# iorx610 register map
Registers are 8-bit, access not given, no defined reset value unless marked. A register's access mark holds for its fields unless they carry their own. Addresses are absolute; registers are grouped by the start of their names; [hi:lo] are bit positions; {n}, {i} and the like mark numbered series; 'fields as' and 'values as' point back to an identical list.

## SFR (part 2 of 2)
0x871FE ICU
  [1:0] ISELR[254].ISEL
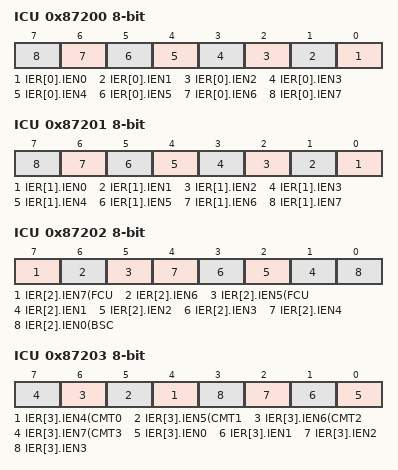
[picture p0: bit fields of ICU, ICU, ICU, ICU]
0x87200 ICU
  [n] IER[0].IEN{n} (n=0..7)
0x87201 ICU
  [n] IER[1].IEN{n} (n=0..7)
0x87202 ICU
  [7] IER[2].IEN7(FCU,FRDYI), [6] IER[2].IEN6, [5] IER[2].IEN5(FCU,FIFERR), [n] IER[2].IEN{n} (n=1..4), [0] IER[2].IEN0(BSC,BUSERR)
0x87203 ICU
  [n] IER[3].IEN{n}(CMT{n-4},CMI{n-4}) (n=4..7), [n] IER[3].IEN{n} (n=0..3)
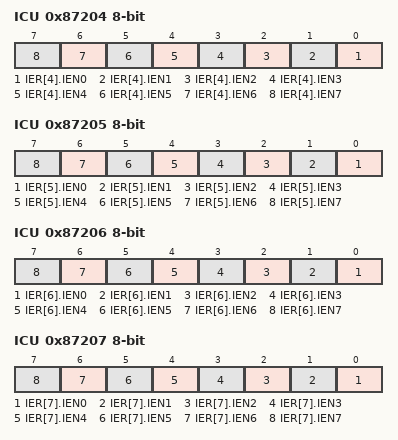
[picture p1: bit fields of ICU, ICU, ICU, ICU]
0x87204 ICU
  [n] IER[4].IEN{n} (n=0..7)
0x87205 ICU
  [n] IER[5].IEN{n} (n=0..7)
0x87206 ICU
  [n] IER[6].IEN{n} (n=0..7)
0x87207 ICU
  [n] IER[7].IEN{n} (n=0..7)
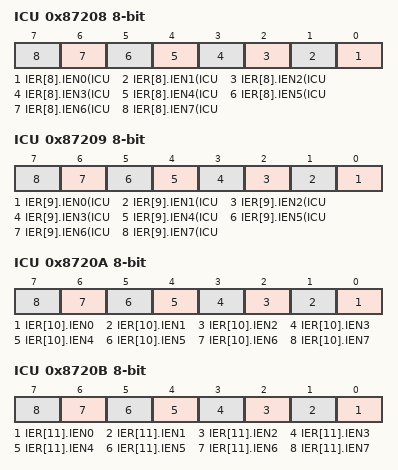
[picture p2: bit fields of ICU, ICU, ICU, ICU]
0x87208 ICU
  [n] IER[8].IEN{n}(ICU,IRQ{n}) (n=0..7)
0x87209 ICU
  [n] IER[9].IEN{n}(ICU,IRQ{n+8}) (n=0..7)
0x8720A ICU
  [n] IER[10].IEN{n} (n=0..7)
0x8720B ICU
  [n] IER[11].IEN{n} (n=0..7)
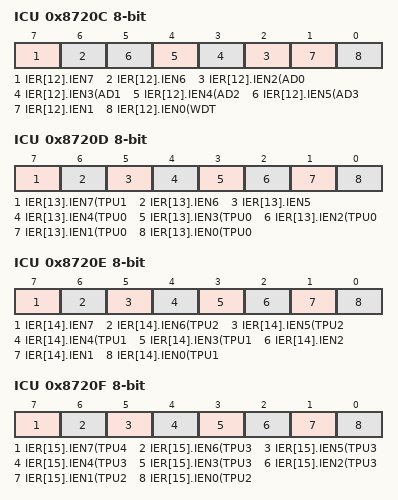
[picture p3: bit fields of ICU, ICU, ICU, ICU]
0x8720C ICU
  [7] IER[12].IEN7, [6] IER[12].IEN6, [n] IER[12].IEN{n}(AD{n-2},ADI{n-2}) (n=2..5), [1] IER[12].IEN1, [0] IER[12].IEN0(WDT,WOVI)
0x8720D ICU
  [7] IER[13].IEN7(TPU1,TGI1A), [6] IER[13].IEN6, [5] IER[13].IEN5, [4] IER[13].IEN4(TPU0,TCI0V), [3] IER[13].IEN3(TPU0,TGI0D), [2] IER[13].IEN2(TPU0,TGI0C), [1] IER[13].IEN1(TPU0,TGI0B), [0] IER[13].IEN0(TPU0,TGI0A)
0x8720E ICU
  [7] IER[14].IEN7, [6] IER[14].IEN6(TPU2,TGI2B), [5] IER[14].IEN5(TPU2,TGI2A), [4] IER[14].IEN4(TPU1,TCI1U), [3] IER[14].IEN3(TPU1,TCI1V), [2] IER[14].IEN2, [1] IER[14].IEN1, [0] IER[14].IEN0(TPU1,TGI1B)
0x8720F ICU
  [7] IER[15].IEN7(TPU4,TGI4A), [6] IER[15].IEN6(TPU3,TCI3V), [5] IER[15].IEN5(TPU3,TGI3D), [4] IER[15].IEN4(TPU3,TGI3C), [3] IER[15].IEN3(TPU3,TGI3B), [2] IER[15].IEN2(TPU3,TGI3A), [1] IER[15].IEN1(TPU2,TCI2U), [0] IER[15].IEN0(TPU2,TCI2V)
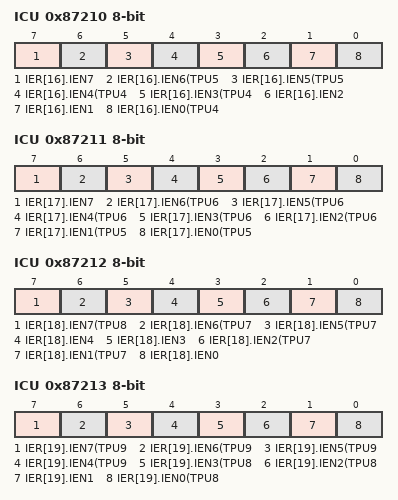
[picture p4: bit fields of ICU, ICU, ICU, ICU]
0x87210 ICU
  [7] IER[16].IEN7, [6] IER[16].IEN6(TPU5,TGI5B), [5] IER[16].IEN5(TPU5,TGI5A), [4] IER[16].IEN4(TPU4,TCI4U), [3] IER[16].IEN3(TPU4,TCI4V), [2] IER[16].IEN2, [1] IER[16].IEN1, [0] IER[16].IEN0(TPU4,TGI4B)
0x87211 ICU
  [7] IER[17].IEN7, [6] IER[17].IEN6(TPU6,TCI6V), [5] IER[17].IEN5(TPU6,TGI6D), [4] IER[17].IEN4(TPU6,TGI6C), [3] IER[17].IEN3(TPU6,TGI6B), [2] IER[17].IEN2(TPU6,TGI6A), [1] IER[17].IEN1(TPU5,TCI5U), [0] IER[17].IEN0(TPU5,TCI5V)
0x87212 ICU
  [7] IER[18].IEN7(TPU8,TGI8A), [6] IER[18].IEN6(TPU7,TCI7U), [5] IER[18].IEN5(TPU7,TCI7V), [4] IER[18].IEN4, [3] IER[18].IEN3, [2] IER[18].IEN2(TPU7,TGI7B), [1] IER[18].IEN1(TPU7,TGI7A), [0] IER[18].IEN0
0x87213 ICU
  [7] IER[19].IEN7(TPU9,TGI9D), [6] IER[19].IEN6(TPU9,TGI9C), [5] IER[19].IEN5(TPU9,TGI9B), [4] IER[19].IEN4(TPU9,TGI9A), [3] IER[19].IEN3(TPU8,TCI8U), [2] IER[19].IEN2(TPU8,TCI8V), [1] IER[19].IEN1, [0] IER[19].IEN0(TPU8,TGI8B)
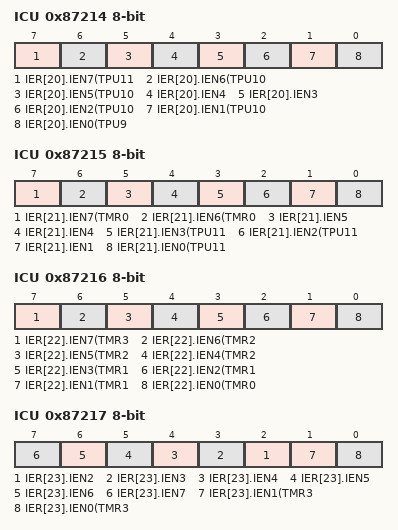
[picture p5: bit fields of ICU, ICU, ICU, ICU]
0x87214 ICU
  [7] IER[20].IEN7(TPU11,TGI11A), [6] IER[20].IEN6(TPU10,TCI10U), [5] IER[20].IEN5(TPU10,TCI10V), [4] IER[20].IEN4, [3] IER[20].IEN3, [2] IER[20].IEN2(TPU10,TGI10B), [1] IER[20].IEN1(TPU10,TGI10A), [0] IER[20].IEN0(TPU9,TCI9V)
0x87215 ICU
  [7] IER[21].IEN7(TMR0,CMIB0), [6] IER[21].IEN6(TMR0,CMIA0), [5] IER[21].IEN5, [4] IER[21].IEN4, [3] IER[21].IEN3(TPU11,TCI11U), [2] IER[21].IEN2(TPU11,TCI11V), [1] IER[21].IEN1, [0] IER[21].IEN0(TPU11,TGI11B)
0x87216 ICU
  [7] IER[22].IEN7(TMR3,CMIA3), [6] IER[22].IEN6(TMR2,OVI2), [5] IER[22].IEN5(TMR2,CMIB2), [4] IER[22].IEN4(TMR2,CMIA2), [3] IER[22].IEN3(TMR1,OVI1), [2] IER[22].IEN2(TMR1,CMIB1), [1] IER[22].IEN1(TMR1,CMIA1), [0] IER[22].IEN0(TMR0,OVI0)
0x87217 ICU
  [n] IER[23].IEN{n} (n=2..7), [1] IER[23].IEN1(TMR3,OVI3), [0] IER[23].IEN0(TMR3,CMIB3)
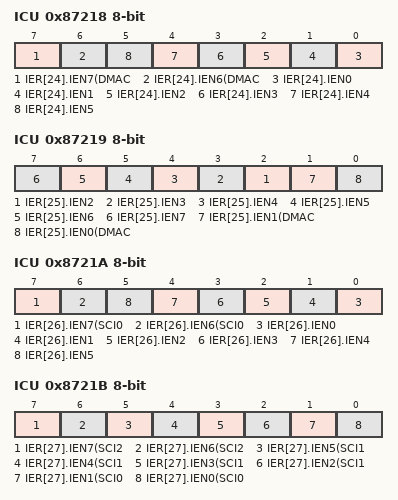
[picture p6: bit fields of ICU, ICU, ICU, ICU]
0x87218 ICU
  [7] IER[24].IEN7(DMAC,DMTEND1), [6] IER[24].IEN6(DMAC,DMTEND0), [n] IER[24].IEN{n} (n=0..5)
0x87219 ICU
  [n] IER[25].IEN{n} (n=2..7), [1] IER[25].IEN1(DMAC,DMTEND3), [0] IER[25].IEN0(DMAC,DMTEND2)
0x8721A ICU
  [7] IER[26].IEN7(SCI0,RXI0), [6] IER[26].IEN6(SCI0,ERI0), [n] IER[26].IEN{n} (n=0..5)
0x8721B ICU
  [7] IER[27].IEN7(SCI2,RXI2), [6] IER[27].IEN6(SCI2,ERI2), [5] IER[27].IEN5(SCI1,TEI1), [4] IER[27].IEN4(SCI1,TXI1), [3] IER[27].IEN3(SCI1,RXI1), [2] IER[27].IEN2(SCI1,ERI1), [1] IER[27].IEN1(SCI0,TEI0), [0] IER[27].IEN0(SCI0,TXI0)
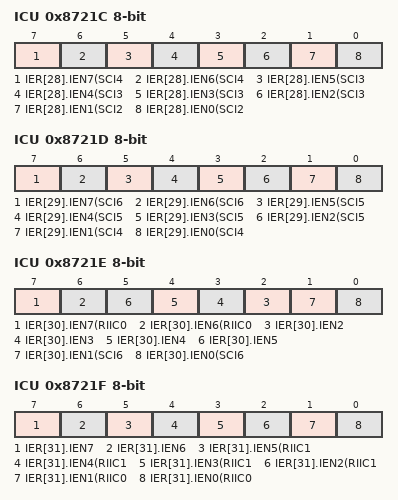
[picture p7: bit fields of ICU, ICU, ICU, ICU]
0x8721C ICU
  [7] IER[28].IEN7(SCI4,RXI4), [6] IER[28].IEN6(SCI4,ERI4), [5] IER[28].IEN5(SCI3,TEI3), [4] IER[28].IEN4(SCI3,TXI3), [3] IER[28].IEN3(SCI3,RXI3), [2] IER[28].IEN2(SCI3,ERI3), [1] IER[28].IEN1(SCI2,TEI2), [0] IER[28].IEN0(SCI2,TXI2)
0x8721D ICU
  [7] IER[29].IEN7(SCI6,RXI6), [6] IER[29].IEN6(SCI6,ERI6), [5] IER[29].IEN5(SCI5,TEI5), [4] IER[29].IEN4(SCI5,TXI5), [3] IER[29].IEN3(SCI5,RXI5), [2] IER[29].IEN2(SCI5,ERI5), [1] IER[29].IEN1(SCI4,TEI4), [0] IER[29].IEN0(SCI4,TXI4)
0x8721E ICU
  [7] IER[30].IEN7(RIIC0,ICRXI0), [6] IER[30].IEN6(RIIC0,ICEEI0), [n] IER[30].IEN{n} (n=2..5), [1] IER[30].IEN1(SCI6,TEI6), [0] IER[30].IEN0(SCI6,TXI6)
0x8721F ICU
  [7] IER[31].IEN7, [6] IER[31].IEN6, [5] IER[31].IEN5(RIIC1,ICTEI1), [4] IER[31].IEN4(RIIC1,ICTXI1), [3] IER[31].IEN3(RIIC1,ICRXI1), [2] IER[31].IEN2(RIIC1,ICEEI1), [1] IER[31].IEN1(RIIC0,ICTEI0), [0] IER[31].IEN0(RIIC0,ICTXI0)
0x87300 ICU
  [2:0] IPR[0](BSC,BUSERR).IPR
0x87301 ICU
  [2:0] IPR[1](FCU,FIFERR).IPR
0x87302 ICU
  [2:0] IPR[2](FCU,FRDYI).IPR
0x87303 ICU
  [2:0] IPR[3].IPR
0x87304 ICU
  [2:0] IPR[4](CMT0,CMI0).IPR
0x87305 ICU
  [2:0] IPR[5](CMT1,CMI1).IPR
0x87306 ICU
  [2:0] IPR[6](CMT2,CMI2).IPR
0x87307 ICU
  [2:0] IPR[7](CMT3,CMI3).IPR
0x87308 ICU
  [2:0] IPR[8].IPR
0x87309 ICU
  [2:0] IPR[9].IPR
0x8730A ICU
  [2:0] IPR[10].IPR
0x8730B ICU
  [2:0] IPR[11].IPR
0x8730C ICU
  [2:0] IPR[12].IPR
0x8730D ICU
  [2:0] IPR[13].IPR
0x8730E ICU
  [2:0] IPR[14].IPR
0x8730F ICU
  [2:0] IPR[15].IPR
0x87310 ICU
  [2:0] IPR[16].IPR
0x87311 ICU
  [2:0] IPR[17].IPR
0x87312 ICU
  [2:0] IPR[18].IPR
0x87313 ICU
  [2:0] IPR[19].IPR
0x87314 ICU
  [2:0] IPR[20].IPR
0x87315 ICU
  [2:0] IPR[21].IPR
0x87316 ICU
  [2:0] IPR[22].IPR
0x87317 ICU
  [2:0] IPR[23].IPR
0x87318 ICU
  [2:0] IPR[24].IPR
0x87319 ICU
  [2:0] IPR[25].IPR
0x8731A ICU
  [2:0] IPR[26].IPR
0x8731B ICU
  [2:0] IPR[27].IPR
0x8731C ICU
  [2:0] IPR[28].IPR
0x8731D ICU
  [2:0] IPR[29].IPR
0x8731E ICU
  [2:0] IPR[30].IPR
0x8731F ICU
  [2:0] IPR[31].IPR
0x87320 ICU
  [2:0] IPR[32](ICU,IRQ0).IPR
0x87321 ICU
  [2:0] IPR[33](ICU,IRQ1).IPR
0x87322 ICU
  [2:0] IPR[34](ICU,IRQ2).IPR
0x87323 ICU
  [2:0] IPR[35](ICU,IRQ3).IPR
0x87324 ICU
  [2:0] IPR[36](ICU,IRQ4).IPR
0x87325 ICU
  [2:0] IPR[37](ICU,IRQ5).IPR
0x87326 ICU
  [2:0] IPR[38](ICU,IRQ6).IPR
0x87327 ICU
  [2:0] IPR[39](ICU,IRQ7).IPR
0x87328 ICU
  [2:0] IPR[40](ICU,IRQ8).IPR
0x87329 ICU
  [2:0] IPR[41](ICU,IRQ9).IPR
0x8732A ICU
  [2:0] IPR[42](ICU,IRQ10).IPR
0x8732B ICU
  [2:0] IPR[43](ICU,IRQ11).IPR
0x8732C ICU
  [2:0] IPR[44](ICU,IRQ12).IPR
0x8732D ICU
  [2:0] IPR[45](ICU,IRQ13).IPR
0x8732E ICU
  [2:0] IPR[46](ICU,IRQ14).IPR
0x8732F ICU
  [2:0] IPR[47](ICU,IRQ15).IPR
0x87330 ICU
  [2:0] IPR[48].IPR
0x87331 ICU
  [2:0] IPR[49].IPR
0x87332 ICU
  [2:0] IPR[50].IPR
0x87333 ICU
  [2:0] IPR[51].IPR
0x87334 ICU
  [2:0] IPR[52].IPR
0x87335 ICU
  [2:0] IPR[53].IPR
0x87336 ICU
  [2:0] IPR[54].IPR
0x87337 ICU
  [2:0] IPR[55].IPR
0x87338 ICU
  [2:0] IPR[56].IPR
0x87339 ICU
  [2:0] IPR[57].IPR
0x8733A ICU
  [2:0] IPR[58].IPR
0x8733B ICU
  [2:0] IPR[59].IPR
0x8733C ICU
  [2:0] IPR[60].IPR
0x8733D ICU
  [2:0] IPR[61].IPR
0x8733E ICU
  [2:0] IPR[62].IPR
0x8733F ICU
  [2:0] IPR[63].IPR
0x87340 ICU
  [2:0] IPR[64](WDT,WOVI).IPR
0x87341 ICU
  [2:0] IPR[65].IPR
0x87342 ICU
  [2:0] IPR[66].IPR
0x87343 ICU
  [2:0] IPR[67].IPR
0x87344 ICU
  [2:0] IPR[68](AD0,ADI0).IPR
0x87345 ICU
  [2:0] IPR[69](AD1,ADI1).IPR
0x87346 ICU
  [2:0] IPR[70](AD2,ADI2).IPR
0x87347 ICU
  [2:0] IPR[71](AD3,ADI3).IPR
0x87348 ICU
  [2:0] IPR[72].IPR
0x87349 ICU
  [2:0] IPR[73].IPR
0x8734A ICU
  [2:0] IPR[74].IPR
0x8734B ICU
  [2:0] IPR[75].IPR
0x8734C ICU
  [2:0] IPR[76](TPU0,TGI0A...).IPR
0x8734D ICU
  [2:0] IPR[77](TPU0,TCI0V).IPR
0x8734E ICU
  [2:0] IPR[78](TPU1,TGI1A...).IPR
0x8734F ICU
  [2:0] IPR[79](TPU1,TCI1V...).IPR
0x87350 ICU
  [2:0] IPR[80](TPU2,TGI2A...).IPR
0x87351 ICU
  [2:0] IPR[81](TPU2,TCI2V...).IPR
0x87352 ICU
  [2:0] IPR[82](TPU3,TGI3A...).IPR
0x87353 ICU
  [2:0] IPR[83](TPU3,TCI3V).IPR
0x87354 ICU
  [2:0] IPR[84](TPU4,TGI4A...).IPR
0x87355 ICU
  [2:0] IPR[85](TPU4,TCI4V...).IPR
0x87356 ICU
  [2:0] IPR[86](TPU5,TGI5A...).IPR
0x87357 ICU
  [2:0] IPR[87](TPU5,TCI5V...).IPR
0x87358 ICU
  [2:0] IPR[88](TPU6,TGI6A...).IPR
0x87359 ICU
  [2:0] IPR[89](TPU6,TCI6V).IPR
0x8735A ICU
  [2:0] IPR[90](TPU7,TGI7A...).IPR
0x8735B ICU
  [2:0] IPR[91](TPU7,TCI7V...).IPR
0x8735C ICU
  [2:0] IPR[92](TPU8,TGI8A...).IPR
0x8735D ICU
  [2:0] IPR[93](TPU8,TCI8V...).IPR
0x8735E ICU
  [2:0] IPR[94](TPU9,TGI9A...).IPR
0x8735F ICU
  [2:0] IPR[95](TPU9,TCI9V).IPR
0x87360 ICU
  [2:0] IPR[96](TPU10,TGI10A...).IPR
0x87361 ICU
  [2:0] IPR[97](TPU10,TCI10V...).IPR
0x87362 ICU
  [2:0] IPR[98](TPU11,TGI11A...).IPR
0x87363 ICU
  [2:0] IPR[99](TPU11,TCI11V...).IPR
0x87364 ICU
  [2:0] IPR[100].IPR
0x87365 ICU
  [2:0] IPR[101].IPR
0x87366 ICU
  [2:0] IPR[102].IPR
0x87367 ICU
  [2:0] IPR[103].IPR
0x87368 ICU
  [2:0] IPR[104](TMR0,CMIA0...).IPR
0x87369 ICU
  [2:0] IPR[105](TMR1,CMIA1...).IPR
0x8736A ICU
  [2:0] IPR[106](TMR2,CMIA2...).IPR
0x8736B ICU
  [2:0] IPR[107](TMR3,CMIA3...).IPR
0x8736C ICU
  [2:0] IPR[108].IPR
0x8736D ICU
  [2:0] IPR[109].IPR
0x8736E ICU
  [2:0] IPR[110].IPR
0x8736F ICU
  [2:0] IPR[111].IPR
0x87370 ICU
  [2:0] IPR[112](DMAC,DMTEND0).IPR
0x87371 ICU
  [2:0] IPR[113](DMAC,DMTEND1).IPR
0x87372 ICU
  [2:0] IPR[114](DMAC,DMTEND2).IPR
0x87373 ICU
  [2:0] IPR[115](DMAC,DMTEND3).IPR
0x87374 ICU
  [2:0] IPR[116].IPR
0x87375 ICU
  [2:0] IPR[117].IPR
0x87376 ICU
  [2:0] IPR[118].IPR
0x87377 ICU
  [2:0] IPR[119].IPR
0x87378 ICU
  [2:0] IPR[120].IPR
0x87379 ICU
  [2:0] IPR[121].IPR
0x8737A ICU
  [2:0] IPR[122].IPR
0x8737B ICU
  [2:0] IPR[123].IPR
0x8737C ICU
  [2:0] IPR[124].IPR
0x8737D ICU
  [2:0] IPR[125].IPR
0x8737E ICU
  [2:0] IPR[126].IPR
0x8737F ICU
  [2:0] IPR[127].IPR
0x87380 ICU
  [2:0] IPR[128](SCI0,ERI0...).IPR
0x87381 ICU
  [2:0] IPR[129](SCI1,ERI1...).IPR
0x87382 ICU
  [2:0] IPR[130](SCI2,ERI2...).IPR
0x87383 ICU
  [2:0] IPR[131](SCI3,ERI3...).IPR
0x87384 ICU
  [2:0] IPR[132](SCI4,ERI4...).IPR
0x87385 ICU
  [2:0] IPR[133](SCI5,ERI5...).IPR
0x87386 ICU
  [2:0] IPR[134](SCI6,ERI6...).IPR
0x87387 ICU
  [2:0] IPR[135].IPR
0x87388 ICU
  [2:0] IPR[136](RIIC0,ICEEI0).IPR
0x87389 ICU
  [2:0] IPR[137](RIIC0,ICRXI0).IPR
0x8738A ICU
  [2:0] IPR[138](RIIC0,ICTXI0).IPR
0x8738B ICU
  [2:0] IPR[139](RIIC0,ICTEI0).IPR
0x8738C ICU
  [2:0] IPR[140](RIIC1,ICEEI1).IPR
0x8738D ICU
  [2:0] IPR[141](RIIC1,ICRXI1).IPR
0x8738E ICU
  [2:0] IPR[142](RIIC1,ICTXI1).IPR
0x8738F ICU
  [2:0] IPR[143](RIIC1,ICTEI1).IPR
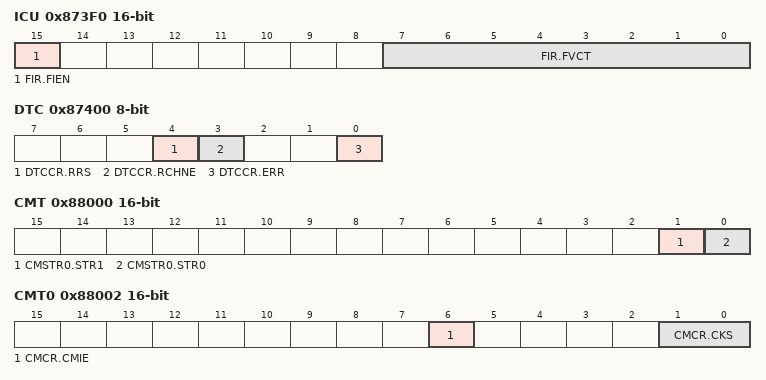
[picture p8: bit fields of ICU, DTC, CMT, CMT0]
0x873F0 ICU 16-bit
  [15] FIR.FIEN, [7:0] FIR.FVCT
0x87400 DTC
  [4] DTCCR.RRS, [3] DTCCR.RCHNE, [0] DTCCR.ERR
0x87408 DTC
  [0] DTCADMOD.SHORT
0x8740C DTC
  [0] DTCST.DTCST
0x88000 CMT 16-bit
  [1] CMSTR0.STR1, [0] CMSTR0.STR0
0x88002 CMT0 16-bit
  [6] CMCR.CMIE, [1:0] CMCR.CKS
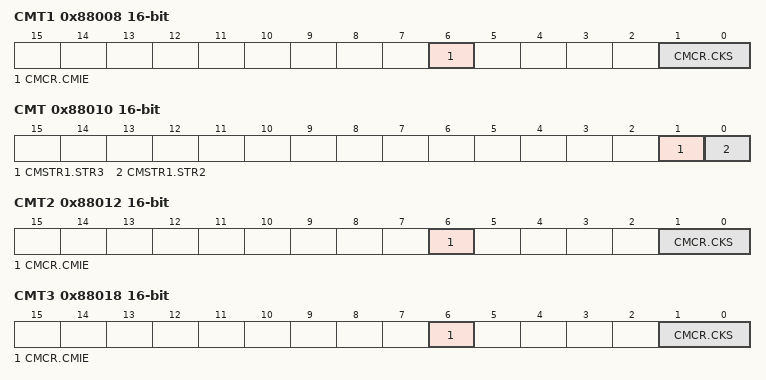
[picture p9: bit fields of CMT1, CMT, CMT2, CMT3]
0x88008 CMT1 16-bit
  [6] CMCR.CMIE, [1:0] CMCR.CKS
0x88010 CMT 16-bit
  [1] CMSTR1.STR3, [0] CMSTR1.STR2
0x88012 CMT2 16-bit
  [6] CMCR.CMIE, [1:0] CMCR.CKS
0x88018 CMT3 16-bit
  [6] CMCR.CMIE, [1:0] CMCR.CKS
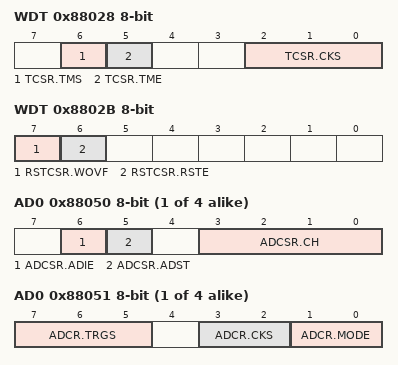
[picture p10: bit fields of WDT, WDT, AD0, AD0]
0x88028 WDT
  [6] TCSR.TMS, [5] TCSR.TME, [2:0] TCSR.CKS
0x8802B WDT
  [7] RSTCSR.WOVF, [6] RSTCSR.RSTE
{0x88050+0x20*i} AD{i} (i=0..3)
  [6] ADCSR.ADIE, [5] ADCSR.ADST, [3:0] ADCSR.CH
{0x88051+0x20*i} AD{i} (i=0..3)
  [7:5] ADCR.TRGS, [3:2] ADCR.CKS, [1:0] ADCR.MODE
{0x88052+0x20*i} AD{i} (i=0..3)
  [7] ADDPR.DPSEL
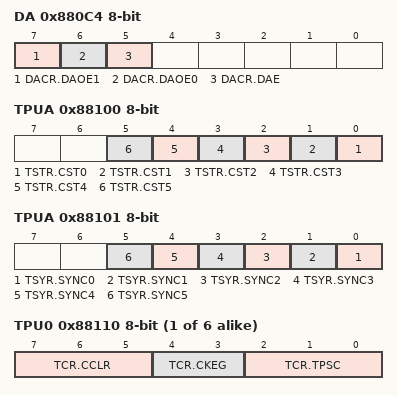
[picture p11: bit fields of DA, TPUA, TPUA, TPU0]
0x880C4 DA
  [7] DACR.DAOE1, [6] DACR.DAOE0, [5] DACR.DAE
0x880C5 DA
  [7] DADPR.DPSEL
0x88100 TPUA
  [n] TSTR.CST{n} (n=0..5)
0x88101 TPUA
  [n] TSYR.SYNC{n} (n=0..5)
{0x88110+0x10*i} TPU{i} (i=0..5)
  [7:5] TCR.CCLR, [4:3] TCR.CKEG, [2:0] TCR.TPSC
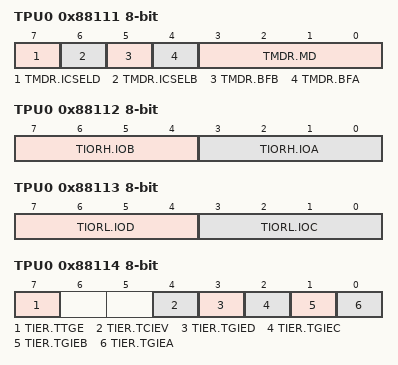
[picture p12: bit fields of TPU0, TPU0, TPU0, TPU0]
0x88111 TPU0
  [7] TMDR.ICSELD, [6] TMDR.ICSELB, [5] TMDR.BFB, [4] TMDR.BFA, [3:0] TMDR.MD
0x88112 TPU0
  [7:4] TIORH.IOB, [3:0] TIORH.IOA
0x88113 TPU0
  [7:4] TIORL.IOD, [3:0] TIORL.IOC
0x88114 TPU0
  [7] TIER.TTGE, [4] TIER.TCIEV, [3] TIER.TGIED, [2] TIER.TGIEC, [1] TIER.TGIEB, [0] TIER.TGIEA
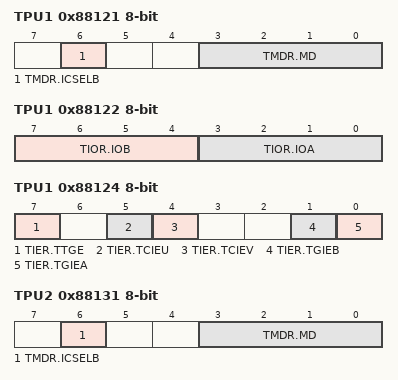
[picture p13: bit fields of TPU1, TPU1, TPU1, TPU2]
0x88121 TPU1
  [6] TMDR.ICSELB, [3:0] TMDR.MD
0x88122 TPU1
  [7:4] TIOR.IOB, [3:0] TIOR.IOA
0x88124 TPU1
  [7] TIER.TTGE, [5] TIER.TCIEU, [4] TIER.TCIEV, [1] TIER.TGIEB, [0] TIER.TGIEA
0x88125 TPU1
  [7] TSR.TCFD
0x88131 TPU2
  [6] TMDR.ICSELB, [3:0] TMDR.MD
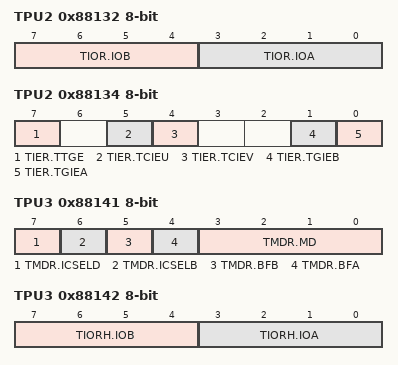
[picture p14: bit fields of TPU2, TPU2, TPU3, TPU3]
0x88132 TPU2
  [7:4] TIOR.IOB, [3:0] TIOR.IOA
0x88134 TPU2
  [7] TIER.TTGE, [5] TIER.TCIEU, [4] TIER.TCIEV, [1] TIER.TGIEB, [0] TIER.TGIEA
0x88135 TPU2
  [7] TSR.TCFD
0x88141 TPU3
  [7] TMDR.ICSELD, [6] TMDR.ICSELB, [5] TMDR.BFB, [4] TMDR.BFA, [3:0] TMDR.MD
0x88142 TPU3
  [7:4] TIORH.IOB, [3:0] TIORH.IOA
0x88143 TPU3
  [7:4] TIORL.IOD, [3:0] TIORL.IOC
0x88144 TPU3
  [7] TIER.TTGE, [4] TIER.TCIEV, [3] TIER.TGIED, [2] TIER.TGIEC, [1] TIER.TGIEB, [0] TIER.TGIEA
0x88151 TPU4
  [6] TMDR.ICSELB, [3:0] TMDR.MD
0x88152 TPU4
  [7:4] TIOR.IOB, [3:0] TIOR.IOA
0x88154 TPU4
  [7] TIER.TTGE, [5] TIER.TCIEU, [4] TIER.TCIEV, [1] TIER.TGIEB, [0] TIER.TGIEA
0x88155 TPU4
  [7] TSR.TCFD
0x88161 TPU5
  [6] TMDR.ICSELB, [3:0] TMDR.MD
0x88162 TPU5
  [7:4] TIOR.IOB, [3:0] TIOR.IOA
0x88164 TPU5
  [7] TIER.TTGE, [5] TIER.TCIEU, [4] TIER.TCIEV, [1] TIER.TGIEB, [0] TIER.TGIEA
0x88165 TPU5
  [7] TSR.TCFD
0x88170 TPUB
  [n] TSTR.CST{n} (n=0..5)
0x88171 TPUB
  [n] TSYR.SYNC{n} (n=0..5)
{0x88120+0x10*i} TPU{i} (i=6..11)
  [7:5] TCR.CCLR, [4:3] TCR.CKEG, [2:0] TCR.TPSC
0x88181 TPU6
  fields as TPU3
0x88182 TPU6
  [7:4] TIORH.IOB, [3:0] TIORH.IOA
0x88183 TPU6
  [7:4] TIORL.IOD, [3:0] TIORL.IOC
0x88184 TPU6
  [7] TIER.TTGE, [4] TIER.TCIEV, [3] TIER.TGIED, [2] TIER.TGIEC, [1] TIER.TGIEB, [0] TIER.TGIEA
0x88191 TPU7
  [6] TMDR.ICSELB, [3:0] TMDR.MD
0x88192 TPU7
  [7:4] TIOR.IOB, [3:0] TIOR.IOA
0x88194 TPU7
  [7] TIER.TTGE, [5] TIER.TCIEU, [4] TIER.TCIEV, [1] TIER.TGIEB, [0] TIER.TGIEA
0x88195 TPU7
  [7] TSR.TCFD
0x881A1 TPU8
  [6] TMDR.ICSELB, [3:0] TMDR.MD
0x881A2 TPU8
  [7:4] TIOR.IOB, [3:0] TIOR.IOA
0x881A4 TPU8
  [7] TIER.TTGE, [5] TIER.TCIEU, [4] TIER.TCIEV, [1] TIER.TGIEB, [0] TIER.TGIEA
0x881A5 TPU8
  [7] TSR.TCFD
0x881B1 TPU9
  fields as TPU3
0x881B2 TPU9
  [7:4] TIORH.IOB, [3:0] TIORH.IOA
0x881B3 TPU9
  [7:4] TIORL.IOD, [3:0] TIORL.IOC
0x881B4 TPU9
  [7] TIER.TTGE, [4] TIER.TCIEV, [3] TIER.TGIED, [2] TIER.TGIEC, [1] TIER.TGIEB, [0] TIER.TGIEA
0x881C1 TPU10
  [6] TMDR.ICSELB, [3:0] TMDR.MD
0x881C2 TPU10
  [7:4] TIOR.IOB, [3:0] TIOR.IOA
0x881C4 TPU10
  [7] TIER.TTGE, [5] TIER.TCIEU, [4] TIER.TCIEV, [1] TIER.TGIEB, [0] TIER.TGIEA
0x881C5 TPU10
  [7] TSR.TCFD
0x881D1 TPU11
  [6] TMDR.ICSELB, [3:0] TMDR.MD
0x881D2 TPU11
  [7:4] TIOR.IOB, [3:0] TIOR.IOA
0x881D4 TPU11
  [7] TIER.TTGE, [5] TIER.TCIEU, [4] TIER.TCIEV, [1] TIER.TGIEB, [0] TIER.TGIEA
0x881D5 TPU11
  [7] TSR.TCFD
0x881E6 PPG0
  [2n+1:2n] PCR.G{n}CMS (n=0..3)
0x881E7 PPG0
  [n+4] PMR.G{n}INV (n=0..3), [n] PMR.G{n}NOV (n=0..3)
0x881E8 PPG0
  [n-8] NDERH.NDER{n} (n=8..15)
0x881E9 PPG0
  [n] NDERL.NDER{n} (n=0..7)
0x881EA PPG0
  [n-8] PODRH.POD{n} (n=8..15)
0x881EB PPG0
  [n] PODRL.POD{n} (n=0..7)
0x881EC PPG0
  [n-8] NDRH.NDR{n} (n=8..15)
0x881ED PPG0
  [n] NDRL.NDR{n} (n=0..7)
0x881EE PPG0
  [n-8] NDRH2.NDR{n} (n=8..11)
0x881EF PPG0
  [n] NDRL2.NDR{n} (n=0..3)
0x881F0 PPG1
  [0] PTRSLR.PTRSL
0x881F6 PPG1
  [2n+1:2n] PCR.G{n}CMS (n=0..3)
0x881F7 PPG1
  [n+4] PMR.G{n}INV (n=0..3), [n] PMR.G{n}NOV (n=0..3)
0x881F8 PPG1
  [n-24] NDERH.NDER{n} (n=24..31)
0x881F9 PPG1
  [n-16] NDERL.NDER{n} (n=16..23)
0x881FA PPG1
  [n-24] PODRH.POD{n} (n=24..31)
0x881FB PPG1
  [n-16] PODRL.POD{n} (n=16..23)
0x881FC PPG1
  [n-24] NDRH.NDR{n} (n=24..31)
0x881FD PPG1
  [n-16] NDRL.NDR{n} (n=16..23)
0x881FE PPG1
  [n-24] NDRH2.NDR{n} (n=24..27)
0x881FF PPG1
  [n-16] NDRL2.NDR{n} (n=16..19)
0x88200 TMR0
  [7] TCR.CMIEB, [6] TCR.CMIEA, [5] TCR.OVIE, [4:3] TCR.CCLR
0x88201 TMR1
  [7] TCR.CMIEB, [6] TCR.CMIEA, [5] TCR.OVIE, [4:3] TCR.CCLR
0x88202 TMR0
  [4] TCSR.ADTE, [3:2] TCSR.OSB, [1:0] TCSR.OSA
0x88203 TMR1
  [3:2] TCSR.OSB, [1:0] TCSR.OSA
0x8820A TMR0
  [7] TCCR.TMRIS, [4:3] TCCR.CSS, [2:0] TCCR.CKS
0x8820B TMR1
  [7] TCCR.TMRIS, [4:3] TCCR.CSS, [2:0] TCCR.CKS
0x88210 TMR2
  [7] TCR.CMIEB, [6] TCR.CMIEA, [5] TCR.OVIE, [4:3] TCR.CCLR
0x88211 TMR3
  [7] TCR.CMIEB, [6] TCR.CMIEA, [5] TCR.OVIE, [4:3] TCR.CCLR
0x88212 TMR2
  [4] TCSR.ADTE, [3:2] TCSR.OSB, [1:0] TCSR.OSA
0x88213 TMR3
  [3:2] TCSR.OSB, [1:0] TCSR.OSA
0x8821A TMR2
  [7] TCCR.TMRIS, [4:3] TCCR.CSS, [2:0] TCCR.CKS
0x8821B TMR3
  [7] TCCR.TMRIS, [4:3] TCCR.CSS, [2:0] TCCR.CKS
{0x88240+8i} SCI{i} (i=0..6)
  [7] SMR.CM, [6] SMR.CHR, [5] SMR.PE, [4] SMR.PM, [3] SMR.STOP, [1:0] SMR.CKS
{0x88240+8i} SMCI{i} (i=0..6)
  [7] SMR.GM, [6] SMR.BLK, [5] SMR.PE, [4] SMR.PM, [3:2] SMR.BCP, [1:0] SMR.CKS
{0x88242+8i} SCI{i} (i=0..6)
  [7] SCR.TIE, [6] SCR.RIE, [5] SCR.TE, [4] SCR.RE, [2] SCR.TEIE, [1:0] SCR.CKE
{0x88242+8i} SMCI{i} (i=0..6)
  [7] SCR.TIE, [6] SCR.RIE, [5] SCR.TE, [4] SCR.RE, [2] SCR.TEIE, [1:0] SCR.CKE
{0x88244+8i} SCI{i} (i=0..6)
  [7] SSR.TDRE, [6] SSR.RDRF, [5] SSR.ORER, [4] SSR.FER, [3] SSR.PER, [2] SSR.TEND
{0x88244+8i} SMCI{i} (i=0..6)
  [7] SSR.TDRE, [6] SSR.RDRF, [5] SSR.ORER, [4] SSR.ERS, [3] SSR.PER, [2] SSR.TEND
{0x88246+8i} SCI{i} (i=0..6)
  [3] SCMR.SDIR, [2] SCMR.SINV, [0] SCMR.SMIF
{0x88246+8i} SMCI{i} (i=0..6)
  [7] SCMR.BCP2, [3] SCMR.SDIR, [2] SCMR.SINV, [0] SCMR.SMIF
{0x88247+8i} SCI{i} (i=0..6)
  [4] SEMR.ABCS, [0] SEMR.ACS0
0x88280 CRC
  [7] CRCCR.DORCLR, [2] CRCCR.LMS, [1:0] CRCCR.GPS
0x88300 RIIC0
  [7] ICCR1.ICE, [6] ICCR1.IICRST, [5] ICCR1.CLO, [4] ICCR1.SOWP, [3] ICCR1.SCLO, [2] ICCR1.SDAO, [1] ICCR1.SCLI, [0] ICCR1.SDAI
0x88301 RIIC0
  [7] ICCR2.BBSY, [6] ICCR2.MST, [5] ICCR2.TRS, [3] ICCR2.SP, [2] ICCR2.RS, [1] ICCR2.ST
0x88302 RIIC0
  [7] ICMR1.MTWP, [6:4] ICMR1.CKS, [3] ICMR1.BCWP, [2:0] ICMR1.BC
0x88303 RIIC0
  [7] ICMR2.DLCS, [6:4] ICMR2.SDDL, [2] ICMR2.TMOH, [1] ICMR2.TMOL, [0] ICMR2.TMOS
0x88304 RIIC0
  [7] ICMR3.SMBS, [6] ICMR3.WAIT, [5] ICMR3.RDRFS, [4] ICMR3.ACKWP, [3] ICMR3.ACKBT, [2] ICMR3.ACKBR, [1:0] ICMR3.NF
0x88305 RIIC0
  [7] ICFER.FMPE, [6] ICFER.SCLE, [5] ICFER.NFE, [4] ICFER.NACKE, [3] ICFER.SALE, [2] ICFER.NALE, [1] ICFER.MALE, [0] ICFER.TMOE
0x88306 RIIC0
  [7] ICSER.HOAE, [5] ICSER.DIDE, [3] ICSER.GCAE, [2] ICSER.SAR2E, [1] ICSER.SAR1E, [0] ICSER.SAR0E
0x88307 RIIC0
  [7] ICIER.TIE, [6] ICIER.TEIE, [5] ICIER.RIE, [4] ICIER.NAKIE, [3] ICIER.SPIE, [2] ICIER.STIE, [1] ICIER.ALIE, [0] ICIER.TMOIE
0x88308 RIIC0
  [7] ICSR1.HOA, [5] ICSR1.DID, [3] ICSR1.GCA, [2] ICSR1.AAS2, [1] ICSR1.AAS1, [0] ICSR1.AAS0
0x88309 RIIC0
  [7] ICSR2.TDRE, [6] ICSR2.TEND, [5] ICSR2.RDRF, [4] ICSR2.NACKF, [3] ICSR2.STOP, [2] ICSR2.START, [1] ICSR2.AL, [0] ICSR2.TMOF
0x8830A RIIC0
  [7:1] SARL0.SVA, [0] SARL0.SVA0
0x8830B RIIC0
  [2:1] SARU0.SVA, [0] SARU0.FS
0x8830C RIIC0
  [7:1] SARL1.SVA, [0] SARL1.SVA0
0x8830D RIIC0
  [2:1] SARU1.SVA, [0] SARU1.FS
0x8830E RIIC0
  [7:1] SARL2.SVA, [0] SARL2.SVA0
0x8830F RIIC0
  [2:1] SARU2.SVA, [0] SARU2.FS
0x88310 RIIC0
  [4:0] ICBRL.BRL
0x88311 RIIC0
  [4:0] ICBRH.BRH
0x88320 RIIC1
  fields as RIIC0
0x88321 RIIC1
  [7] ICCR2.BBSY, [6] ICCR2.MST, [5] ICCR2.TRS, [3] ICCR2.SP, [2] ICCR2.RS, [1] ICCR2.ST
0x88322 RIIC1
  [7] ICMR1.MTWP, [6:4] ICMR1.CKS, [3] ICMR1.BCWP, [2:0] ICMR1.BC
0x88323 RIIC1
  [7] ICMR2.DLCS, [6:4] ICMR2.SDDL, [2] ICMR2.TMOH, [1] ICMR2.TMOL, [0] ICMR2.TMOS
0x88324 RIIC1
  [7] ICMR3.SMBS, [6] ICMR3.WAIT, [5] ICMR3.RDRFS, [4] ICMR3.ACKWP, [3] ICMR3.ACKBT, [2] ICMR3.ACKBR, [1:0] ICMR3.NF
0x88325 RIIC1
  [7] ICFER.FMPE, [6] ICFER.SCLE, [5] ICFER.NFE, [4] ICFER.NACKE, [3] ICFER.SALE, [2] ICFER.NALE, [1] ICFER.MALE, [0] ICFER.TMOE
0x88326 RIIC1
  [7] ICSER.HOAE, [5] ICSER.DIDE, [3] ICSER.GCAE, [2] ICSER.SAR2E, [1] ICSER.SAR1E, [0] ICSER.SAR0E
0x88327 RIIC1
  [7] ICIER.TIE, [6] ICIER.TEIE, [5] ICIER.RIE, [4] ICIER.NAKIE, [3] ICIER.SPIE, [2] ICIER.STIE, [1] ICIER.ALIE, [0] ICIER.TMOIE
0x88328 RIIC1
  [7] ICSR1.HOA, [5] ICSR1.DID, [3] ICSR1.GCA, [2] ICSR1.AAS2, [1] ICSR1.AAS1, [0] ICSR1.AAS0
0x88329 RIIC1
  [7] ICSR2.TDRE, [6] ICSR2.TEND, [5] ICSR2.RDRF, [4] ICSR2.NACKF, [3] ICSR2.STOP, [2] ICSR2.START, [1] ICSR2.AL, [0] ICSR2.TMOF
0x8832A RIIC1
  [7:1] SARL0.SVA, [0] SARL0.SVA0
0x8832B RIIC1
  [2:1] SARU0.SVA, [0] SARU0.FS
0x8832C RIIC1
  [7:1] SARL1.SVA, [0] SARL1.SVA0
0x8832D RIIC1
  [2:1] SARU1.SVA, [0] SARU1.FS
0x8832E RIIC1
  [7:1] SARL2.SVA, [0] SARL2.SVA0
0x8832F RIIC1
  [2:1] SARU2.SVA, [0] SARU2.FS
0x88330 RIIC1
  [4:0] ICBRL.BRL
0x88331 RIIC1
  [4:0] ICBRH.BRH
0x8C000 PORT0
  [n] DDR.B{n} (n=0..5)
{0x8C000+i} PORT{i} (i=1..7)
  [n] DDR.B{n} (n=0..7)
0x8C008 PORT8
  [n] DDR.B{n} (n=0..6)
0x8C009 PORT9
  [n] DDR.B{n} (n=0..7)
0x8C00A PORTA
  [n] DDR.B{n} (n=0..7)
0x8C00B PORTB
  [n] DDR.B{n} (n=0..7)
0x8C00C PORTC
  [n] DDR.B{n} (n=0..7)
0x8C00D PORTD
  [n] DDR.B{n} (n=0..7)
0x8C00E PORTE
  [n] DDR.B{n} (n=0..7)
0x8C00F PORTF
  [n] DDR.B{n} (n=0..6)
0x8C010 PORTG
  [n] DDR.B{n} (n=0..7)
0x8C011 PORTH
  [n] DDR.B{n} (n=0..7)
0x8C020 PORT0
  [n] DR.B{n} (n=0..5)
{0x8C020+i} PORT{i} (i=1..7)
  [n] DR.B{n} (n=0..7)
0x8C028 PORT8
  [n] DR.B{n} (n=0..6)
0x8C029 PORT9
  [n] DR.B{n} (n=0..7)
0x8C02A PORTA
  [n] DR.B{n} (n=0..7)
0x8C02B PORTB
  [n] DR.B{n} (n=0..7)
0x8C02C PORTC
  [n] DR.B{n} (n=0..7)
0x8C02D PORTD
  [n] DR.B{n} (n=0..7)
0x8C02E PORTE
  [n] DR.B{n} (n=0..7)
0x8C02F PORTF
  [n] DR.B{n} (n=0..6)
0x8C030 PORTG
  [n] DR.B{n} (n=0..7)
0x8C031 PORTH
  [n] DR.B{n} (n=0..7)
0x8C040 PORT0
  [n] PORT.B{n} (n=0..5)
{0x8C040+i} PORT{i} (i=1..7)
  [n] PORT.B{n} (n=0..7)
0x8C048 PORT8
  [n] PORT.B{n} (n=0..6)
0x8C049 PORT9
  [n] PORT.B{n} (n=0..7)
0x8C04A PORTA
  [n] PORT.B{n} (n=0..7)
0x8C04B PORTB
  [n] PORT.B{n} (n=0..7)
0x8C04C PORTC
  [n] PORT.B{n} (n=0..7)
0x8C04D PORTD
  [n] PORT.B{n} (n=0..7)
0x8C04E PORTE
  [n] PORT.B{n} (n=0..7)
0x8C04F PORTF
  [n] PORT.B{n} (n=0..6)
0x8C050 PORTG
  [n] PORT.B{n} (n=0..7)
0x8C051 PORTH
  [n] PORT.B{n} (n=0..7)
0x8C060 PORT0
  [n] ICR.B{n} (n=0..5)
{0x8C060+i} PORT{i} (i=1..7)
  [n] ICR.B{n} (n=0..7)
0x8C068 PORT8
  [n] ICR.B{n} (n=0..6)
0x8C069 PORT9
  [n] ICR.B{n} (n=0..7)
0x8C06A PORTA
  [n] ICR.B{n} (n=0..7)
0x8C06B PORTB
  [n] ICR.B{n} (n=0..7)
0x8C06C PORTC
  [n] ICR.B{n} (n=0..7)
0x8C06D PORTD
  [n] ICR.B{n} (n=0..7)
0x8C06E PORTE
  [n] ICR.B{n} (n=0..7)
0x8C06F PORTF
  [n] ICR.B{n} (n=0..6)
0x8C070 PORTG
  [n] ICR.B{n} (n=0..7)
0x8C071 PORTH
  [n] ICR.B{n} (n=0..7)
0x8C082 PORT2
  [n] ODR.B{n} (n=0..7)
0x8C08C PORTC
  [n] ODR.B{n} (n=0..7)
0x8C0CA PORTA
  [n] PCR.B{n} (n=0..7)
0x8C0CB PORTB
  [n] PCR.B{n} (n=0..7)
0x8C0CC PORTC
  [n] PCR.B{n} (n=0..7)
0x8C0CD PORTD
  [n] PCR.B{n} (n=0..7)
0x8C0CE PORTE
  [n] PCR.B{n} (n=0..7)
0x8C100 IOPORT
  [n] PFCR0.CS{n}E (n=0..7)
0x8C101 IOPORT
  [2n-7:2n-8] PFCR1.CS{n}S (n=4..7)
0x8C102 IOPORT
  [7] PFCR2.CS3S, [6] PFCR2.CS2S
0x8C103 IOPORT
  [n-16] PFCR3.A{n}E (n=16..23)
0x8C104 IOPORT
  [n-8] PFCR4.A{n}E (n=8..15)
0x8C105 IOPORT
  [6] PFCR5.WR1BC1E, [4] PFCR5.DHE, [3] PFCR5.TCLKS
0x8C106 IOPORT
  [7] PFCR6.TPUMS5, [6] PFCR6.TPUMS4, [5] PFCR6.TPUMS3A, [4] PFCR6.TPUMS3B, [3] PFCR6.TPUMS2, [2] PFCR6.TPUMS1, [1] PFCR6.TPUMS0A, [0] PFCR6.TPUMS0B
0x8C107 IOPORT
  [7] PFCR7.TPUMS11, [6] PFCR7.TPUMS10, [5] PFCR7.TPUMS9A, [4] PFCR7.TPUMS9B, [3] PFCR7.TPUMS8, [2] PFCR7.TPUMS7, [1] PFCR7.TPUMS6A, [0] PFCR7.TPUMS6B
0x8C108 IOPORT
  [n-8] PFCR8.ITS{n} (n=8..15)
0x8C109 IOPORT
  [n] PFCR9.ITS{n} (n=0..7)
0x8C280 SYSTEM
  [7] DPSBYCR.DPSBY, [6] DPSBYCR.IOKEEP, [5] DPSBYCR.RAMCUT2, [4] DPSBYCR.RAMCUT1, [0] DPSBYCR.RAMCUT0
0x8C281 SYSTEM
  [5:0] DPSWCR.WTSTS
0x8C282 SYSTEM
  [7] DPSIER.DNMIE, [n] DPSIER.DIRQ{n}E (n=0..3)
0x8C283 SYSTEM
  [7] DPSIFR.DNMIF, [n] DPSIFR.DIRQ{n}F (n=0..3)
0x8C284 SYSTEM
  [7] DPSIEGR.DNMIEG, [n] DPSIEGR.DIRQ{n}EG (n=0..3)
0x8C285 SYSTEM
  [7] RSTSR.DPSRSTF
0x8C289 FLASH
  [1:0] FWEPROR.FLWE
0x8C300 ICU
  [0] IRQER[0].IRQEN
0x8C301 ICU
  [0] IRQER[1].IRQEN
0x8C302 ICU
  [0] IRQER[2].IRQEN
0x8C303 ICU
  [0] IRQER[3].IRQEN
0x8C304 ICU
  [0] IRQER[4].IRQEN
0x8C305 ICU
  [0] IRQER[5].IRQEN
0x8C306 ICU
  [0] IRQER[6].IRQEN
0x8C307 ICU
  [0] IRQER[7].IRQEN
0x8C308 ICU
  [0] IRQER[8].IRQEN
0x8C309 ICU
  [0] IRQER[9].IRQEN
0x8C30A ICU
  [0] IRQER[10].IRQEN
0x8C30B ICU
  [0] IRQER[11].IRQEN
0x8C30C ICU
  [0] IRQER[12].IRQEN
0x8C30D ICU
  [0] IRQER[13].IRQEN
0x8C30E ICU
  [0] IRQER[14].IRQEN
0x8C30F ICU
  [0] IRQER[15].IRQEN
0x8C320 ICU
  [3:2] IRQCR[0].IRQMD
0x8C321 ICU
  [3:2] IRQCR[1].IRQMD
0x8C322 ICU
  [3:2] IRQCR[2].IRQMD
0x8C323 ICU
  [3:2] IRQCR[3].IRQMD
0x8C324 ICU
  [3:2] IRQCR[4].IRQMD
0x8C325 ICU
  [3:2] IRQCR[5].IRQMD
0x8C326 ICU
  [3:2] IRQCR[6].IRQMD
0x8C327 ICU
  [3:2] IRQCR[7].IRQMD
0x8C328 ICU
  [3:2] IRQCR[8].IRQMD
0x8C329 ICU
  [3:2] IRQCR[9].IRQMD
0x8C32A ICU
  [3:2] IRQCR[10].IRQMD
0x8C32B ICU
  [3:2] IRQCR[11].IRQMD
0x8C32C ICU
  [3:2] IRQCR[12].IRQMD
0x8C32D ICU
  [3:2] IRQCR[13].IRQMD
0x8C32E ICU
  [3:2] IRQCR[14].IRQMD
0x8C32F ICU
  [3:2] IRQCR[15].IRQMD
0x8C340 ICU 16-bit
  [n] SSIER.SSI{n} (n=0..15)
0x8C350 ICU
  [0] NMIER.NMIEN
0x8C351 ICU
  [3] NMICR.NMIMD
0x8C352 ICU
  [0] NMISR.NMIST
0x8C353 ICU
  [0] NMICLR.NMICLR
0x7FC402 FLASH
  [4] FMODR.FRDMD
0x7FC410 FLASH
  [7] FASTAT.ROMAE, [4] FASTAT.CMDLK, [3] FASTAT.DFLAE, [1] FASTAT.DFLRPE, [0] FASTAT.DFLWPE
0x7FC411 FLASH
  [7] FAEINT.ROMAEIE, [4] FAEINT.CMDLKIE, [3] FAEINT.DFLAEIE, [1] FAEINT.DFLRPEIE, [0] FAEINT.DFLWPEIE
0x7FC412 FLASH
  [0] FRDYIE.FRDYIE
0x7FC440 FLASH 16-bit
  [15:8] DFLRE.KEY, [n] DFLRE.DBRE{n} (n=0..3)
0x7FC450 FLASH 16-bit
  [15:8] DFLWE.KEY, [n] DFLWE.DBWE{n} (n=0..3)
0x7FC454 FLASH 16-bit
  [15:8] FCURAME.KEY, [0] FCURAME.FCRME
0x7FFFB0 FLASH
  [7] FSTATR0.FRDY, [6] FSTATR0.ILGLERR, [5] FSTATR0.ERSERR, [4] FSTATR0.PRGERR, [3] FSTATR0.SUSRDY, [1] FSTATR0.ERSSPD, [0] FSTATR0.PRGSPD
0x7FFFB1 FLASH
  [7] FSTATR1.FCUERR, [4] FSTATR1.FLOCKST
0x7FFFB2 FLASH 16-bit
  [15:8] FENTRYR.FEKEY, [7] FENTRYR.FENTRYD, [1] FENTRYR.FENTRY1, [0] FENTRYR.FENTRY0
0x7FFFB4 FLASH 16-bit
  [15:8] FPROTR.FPKEY, [0] FPROTR.FPROTCN
0x7FFFB6 FLASH 16-bit
  [15:8] FRESETR.FRKEY, [0] FRESETR.FRESET
0x7FFFBA FLASH 16-bit
  [15:8] FCMDR.CMDR, [7:0] FCMDR.PCMDR
0x7FFFC8 FLASH 16-bit
  [0] FCPSR.ESUSPMD
0x7FFFCA FLASH 16-bit
  [12:3] DFLBCCNT.BCADR, [0] DFLBCCNT.BCSIZE
0x7FFFCC FLASH 16-bit
  [7:0] FPESTAT.PEERRST
0x7FFFCE FLASH 16-bit
  [0] DFLBCSTAT.BCST
0x7FFFE8 FLASH 16-bit
  [7:0] PCKAR.PCKA
